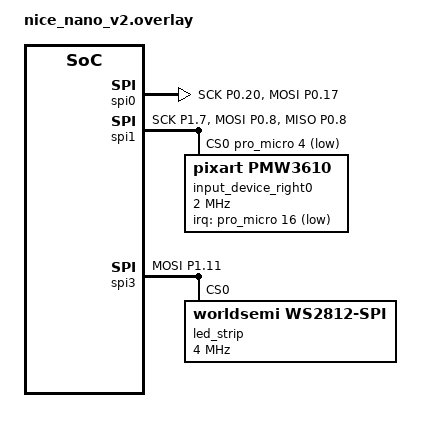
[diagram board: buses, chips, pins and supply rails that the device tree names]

/**
 * Generated by Shield Wizard for ZMK
 * Applies to shield "splayt_right" with board "nice_nano_v2" only
 */

//
// ======== spi0 ========
// ==== (Nice!View) =====

// pin control for spi0
// - SCK on D3
// - MOSI on D2
&pinctrl {
    /* configuration for spi0 device, default state */
    spi0_default: spi0_default {
        group1 {
            psels = <NRF_PSEL(SPIM_SCK, 0, 20)>,
                    <NRF_PSEL(SPIM_MOSI, 0, 17)>;
        };
    };
    /* configuration for spi0 device, sleep state */
    spi0_sleep: spi0_sleep {
        group1 {
            psels = <NRF_PSEL(SPIM_SCK, 0, 20)>,
                    <NRF_PSEL(SPIM_MOSI, 0, 17)>;
            low-power-enable;
        };
    };
};
&spi0 {
  compatible = "nordic,nrf-spim";
  status = "okay";
  pinctrl-0 = <&spi0_default>;
  pinctrl-1 = <&spi0_sleep>;
  pinctrl-names = "default", "sleep";
};

// devices on spi0

// CS pins for devices on spi0
&spi0 {
    cs-gpios = <&pro_micro 1 GPIO_ACTIVE_HIGH>;
};

// Label spi0 as nice_view_spi,
// The actual device node is defined in the `nice_view` shield.
nice_view_spi: &spi0 { };

//
// ======== spi1 ========
// ==== (Trackball) =====

// pin control for spi1
// - SCK on P1.07
// - MOSI on D0
// - MISO on D0
&pinctrl {
    /* configuration for spi1 device, default state */
    spi1_default: spi1_default {
        group1 {
            psels = <NRF_PSEL(SPIM_SCK, 1, 7)>,  // SCLK pin
                    <NRF_PSEL(SPIM_MOSI, 0, 8)>, // SDIO pin
                    <NRF_PSEL(SPIM_MISO, 0, 8)>; // SDIO pin (also)
        };
    };
    /* configuration for spi1 device, sleep state */
    spi1_sleep: spi1_sleep {
        group1 {
            psels = <NRF_PSEL(SPIM_SCK, 1, 7)>,  // SCLK pin
                    <NRF_PSEL(SPIM_MOSI, 0, 8)>, // SDIO pin
                    <NRF_PSEL(SPIM_MISO, 0, 8)>; // SDIO pin (also)
            low-power-enable;
        };
    };
};
&spi1 {
  compatible = "nordic,nrf-spim";
  status = "okay";
  pinctrl-0 = <&spi1_default>;
  pinctrl-1 = <&spi1_sleep>;
  pinctrl-names = "default", "sleep";
};

// devices on spi1

// CS pins for devices on spi1
&spi1 {
    cs-gpios = <&pro_micro 4 GPIO_ACTIVE_LOW>;
};

#include <zephyr/dt-bindings/input/input-event-codes.h>

&spi1 {
    input_device_right0: input_device_right0@0 {
        status = "okay";
        compatible = "pixart,pmw3610";
        reg = <0>;
        spi-max-frequency = <2000000>;
        evt-type = <INPUT_EV_REL>;
        x-input-code = <INPUT_REL_X>;
        y-input-code = <INPUT_REL_Y>;
        irq-gpios = <&pro_micro 16 (GPIO_ACTIVE_LOW | GPIO_PULL_UP)>; // MOT pin
        cpi = <600>;
        // swap-xy; /* optional */
        // invert-x; /* optional */
        // invert-y; /* optional */

        //force-awake;
        /* keep the sensor awake while ZMK activity state is ACTIVE,
           fallback to normal downshift mode after ZMK goes into IDLE / SLEEP mode.
           thus, the sensor would be a `wakeup-source` */

        //force-awake-4ms-mode;
        /* while force-awake is acitvated, enable this mode to force sampling per 
           4ms, where the default sampling rate is 8ms. */
        /* NOTE: apply this mode if you need 250Hz with direct USB connection. */
    };
};

// / {
//   trackball_listener {
//     compatible = "zmk,input-listener";
//     device = <&trackball>;
//   };
// };

//
// ======== spi3 ========
// ======= (LEDs) =======

// pin control for spi3
// - MOSI on D14
&pinctrl {
    /* configuration for spi3 device, default state */
    spi3_default: spi3_default {
        group1 {
            psels = <NRF_PSEL(SPIM_MOSI, 1, 11)>;
        };
    };
    /* configuration for spi3 device, sleep state */
    spi3_sleep: spi3_sleep {
        group1 {
            psels = <NRF_PSEL(SPIM_MOSI, 1, 11)>;
            low-power-enable;
        };
    };
};
&spi3 {
  compatible = "nordic,nrf-spim";
  status = "okay";
  pinctrl-0 = <&spi3_default>;
  pinctrl-1 = <&spi3_sleep>;
  pinctrl-names = "default", "sleep";
};

// devices on spi3

#include <dt-bindings/led/led.h>
&spi3 {
    led_strip: ws2812@0 {
        compatible = "worldsemi,ws2812-spi";
        reg = <0>;
        spi-max-frequency = <4000000>;

        chain-length = <28>;
        spi-one-frame = <0x70>;
        spi-zero-frame = <0x40>;
        color-mapping = <LED_COLOR_ID_GREEN
                         LED_COLOR_ID_RED
                         LED_COLOR_ID_BLUE>;
    };
};
/ {
    chosen {
        zmk,underglow = &led_strip;
    };
};
